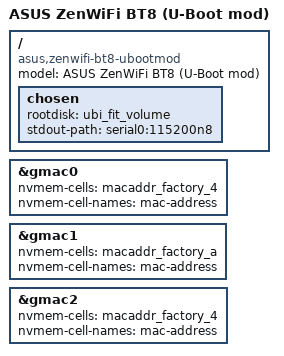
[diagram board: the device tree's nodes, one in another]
// SPDX-License-Identifier: (GPL-2.0 OR MIT)

#include "mt7988d-asus-zenwifi-bt8.dtsi"

/ {
	model = "ASUS ZenWiFi BT8 (U-Boot mod)";
	compatible = "asus,zenwifi-bt8-ubootmod", "mediatek,mt7988a";

	chosen {
		rootdisk = <&ubi_fit_volume>;
		stdout-path = "serial0:115200n8";
	};
};

&gmac0 {
	nvmem-cells = <&macaddr_factory_4>;
	nvmem-cell-names = "mac-address";
};

&gmac1 {
	nvmem-cells = <&macaddr_factory_a>;
	nvmem-cell-names = "mac-address";
};

&gmac2 {
	nvmem-cells = <&macaddr_factory_4>;
	nvmem-cell-names = "mac-address";
};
